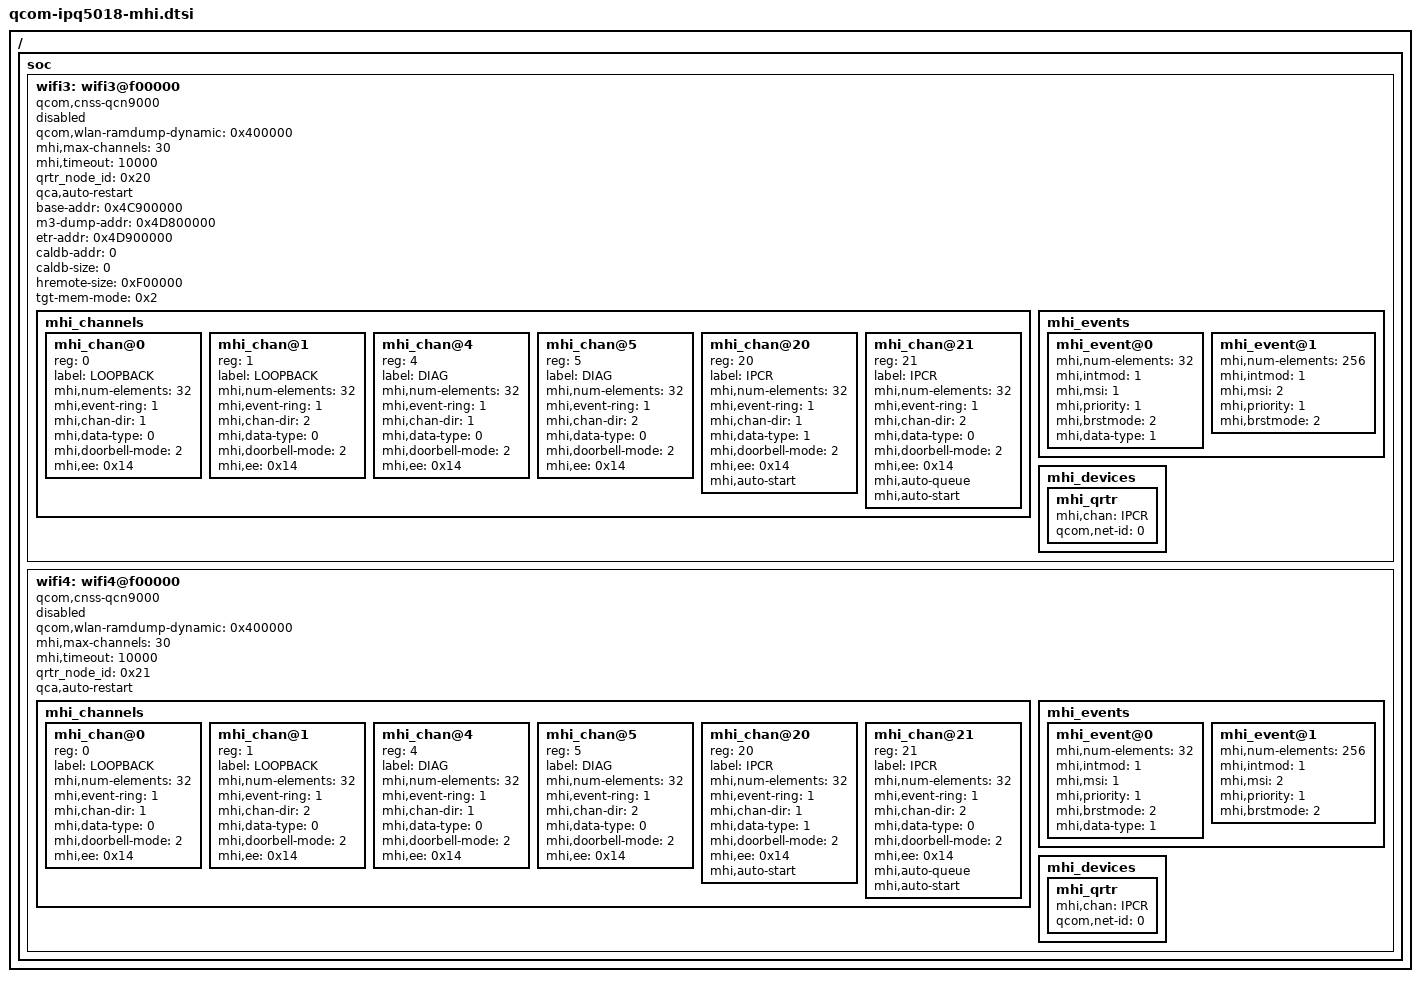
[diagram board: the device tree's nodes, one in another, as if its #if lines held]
/*
 * Copyright (c) 2017, 2020, The Linux Foundation. All rights reserved.
 *
 * Permission to use, copy, modify, and/or distribute this software for any
 * purpose with or without fee is hereby granted, provided that the above
 * copyright notice and this permission notice appear in all copies.
 *
 * THE SOFTWARE IS PROVIDED "AS IS" AND THE AUTHOR DISCLAIMS ALL WARRANTIES
 * WITH REGARD TO THIS SOFTWARE INCLUDING ALL IMPLIED WARRANTIES OF
 * MERCHANTABILITY AND FITNESS. IN NO EVENT SHALL THE AUTHOR BE LIABLE FOR
 * ANY SPECIAL, DIRECT, INDIRECT, OR CONSEQUENTIAL DAMAGES OR ANY DAMAGES
 * WHATSOEVER RESULTING FROM LOSS OF USE, DATA OR PROFITS, WHETHER IN AN
 * ACTION OF CONTRACT, NEGLIGENCE OR OTHER TORTIOUS ACTION, ARISING OUT OF
 * OR IN CONNECTION WITH THE USE OR PERFORMANCE OF THIS SOFTWARE.
 */


/ {

	soc {
		wifi3: wifi3@f00000 {
			compatible  = "qcom,cnss-qcn9000";
			qcom,wlan-ramdump-dynamic = <0x400000>;
			mhi,max-channels = <30>;
			mhi,timeout = <10000>;
			qrtr_node_id = <0x20>;
			qca,auto-restart;
#ifdef __IPQ_MEM_PROFILE_256_MB__
			/* QCN9000 tgt-mem-mode=2 layout - 17MB
			 * +=========+==============+=========+
			 * |  Region | Start Offset |   Size  |
			 * +---------+--------------+---------+
			 * | HREMOTE |  0x4C900000  |   15MB  |
			 * +---------+--------------+---------+
			 * | M3 Dump |  0x4D800000  |   1MB   |
			 * +---------+--------------+---------+
			 * |   ETR   |  0x4D900000  |   1MB   |
			 * +==================================+
			 */
			base-addr = <0x4C900000>;
			m3-dump-addr = <0x4D800000>;
			etr-addr = <0x4D900000>;
			caldb-addr = <0>;
			caldb-size = <0>;
			hremote-size = <0xF00000>;
			tgt-mem-mode = <0x2>;
#elif __IPQ_MEM_PROFILE_512_MB__
			/* QCN9000 tgt-mem-mode=1 layout - 30MB
			 * +=========+==============+=========+
			 * |  Region | Start Offset |   Size  |
			 * +---------+--------------+---------+
			 * | HREMOTE |  0x4CC00000  |   20MB  |
			 * +---------+--------------+---------+
			 * | M3 Dump |  0x4E000000  |   1MB   |
			 * +---------+--------------+---------+
			 * |   ETR   |  0x4E100000  |   1MB   |
			 * +---------+--------------+---------+
			 * |  Caldb  |  0x4E200000  |   8MB   |
			 * +==================================+
			 */
			base-addr = <0x4CC00000>;
			m3-dump-addr = <0x4E000000>;
			etr-addr = <0x4E100000>;
			caldb-addr = <0x4E200000>;
			caldb-size = <0x800000>;
			hremote-size = <0x1400000>;
			tgt-mem-mode = <0x1>;
#else
			/* QCN9000 tgt-mem-mode=0 layout - 45MB
		       * +=========+==============+=========+
		       * |  Region | Start Offset |   Size  |
		       * +---------+--------------+---------+
		       * | HREMOTE |  0x4CC00000  |   35MB  |
		       * +---------+--------------+---------+
		       * | M3 Dump |  0x4EF00000  |   1MB   |
		       * +---------+--------------+---------+
		       * |   ETR   |  0x4F000000  |   1MB   |
		       * +---------+--------------+---------+
		       * |  Caldb  |  0x4F100000  |   8MB   |
		       * +==================================+
		       */
			base-addr = <0x4CC00000>;
			m3-dump-addr = <0x4EF00000>;
			etr-addr = <0x4F000000>;
			caldb-addr = <0x4F100000>;
			hremote-size = <0x2300000>;
			caldb-size = <0x800000>;
			tgt-mem-mode = <0x0>;
#endif
			status = "disabled";

			#address-cells = <1>;
			#size-cells = <0>;

			mhi_channels {
				mhi_chan@0 {
					reg = <0>;
					label = "LOOPBACK";
					mhi,num-elements = <32>;
					mhi,event-ring = <1>;
					mhi,chan-dir = <1>;
					mhi,data-type = <0>;
					mhi,doorbell-mode = <2>;
					mhi,ee = <0x14>;
				};

				mhi_chan@1 {
					reg = <1>;
					label = "LOOPBACK";
					mhi,num-elements = <32>;
					mhi,event-ring = <1>;
					mhi,chan-dir = <2>;
					mhi,data-type = <0>;
					mhi,doorbell-mode = <2>;
					mhi,ee = <0x14>;
				};

				mhi_chan@4 {
					reg = <4>;
					label = "DIAG";
					mhi,num-elements = <32>;
					mhi,event-ring = <1>;
					mhi,chan-dir = <1>;
					mhi,data-type = <0>;
					mhi,doorbell-mode = <2>;
					mhi,ee = <0x14>;
				};

				mhi_chan@5 {
					reg = <5>;
					label = "DIAG";
					mhi,num-elements = <32>;
					mhi,event-ring = <1>;
					mhi,chan-dir = <2>;
					mhi,data-type = <0>;
					mhi,doorbell-mode = <2>;
					mhi,ee = <0x14>;
				};

				mhi_chan@20 {
					reg = <20>;
					label = "IPCR";
					mhi,num-elements = <32>;
					mhi,event-ring = <1>;
					mhi,chan-dir = <1>;
					mhi,data-type = <1>;
					mhi,doorbell-mode = <2>;
					mhi,ee = <0x14>;
					mhi,auto-start;
				};

				mhi_chan@21 {
					reg = <21>;
					label = "IPCR";
					mhi,num-elements = <32>;
					mhi,event-ring = <1>;
					mhi,chan-dir = <2>;
					mhi,data-type = <0>;
					mhi,doorbell-mode = <2>;
					mhi,ee = <0x14>;
					mhi,auto-queue;
					mhi,auto-start;
				};
			};

			mhi_events {
				mhi_event@0 {
					mhi,num-elements = <32>;
					mhi,intmod = <1>;
					mhi,msi = <1>;
					mhi,priority = <1>;
					mhi,brstmode = <2>;
					mhi,data-type = <1>;
				};

				mhi_event@1 {
					mhi,num-elements = <256>;
					mhi,intmod = <1>;
					mhi,msi = <2>;
					mhi,priority = <1>;
					mhi,brstmode = <2>;
				};
			};

			mhi_devices {
				mhi_qrtr {
					mhi,chan = "IPCR";
					qcom,net-id = <0>;
				};
			};
		};

		wifi4: wifi4@f00000 {
			compatible  = "qcom,cnss-qcn9000";
			qcom,wlan-ramdump-dynamic = <0x400000>;
			mhi,max-channels = <30>;
			mhi,timeout = <10000>;
			qrtr_node_id = <0x21>;
			qca,auto-restart;
			status = "disabled";

			#address-cells = <1>;
			#size-cells = <0>;

			mhi_channels {
				mhi_chan@0 {
					reg = <0>;
					label = "LOOPBACK";
					mhi,num-elements = <32>;
					mhi,event-ring = <1>;
					mhi,chan-dir = <1>;
					mhi,data-type = <0>;
					mhi,doorbell-mode = <2>;
					mhi,ee = <0x14>;
				};

				mhi_chan@1 {
					reg = <1>;
					label = "LOOPBACK";
					mhi,num-elements = <32>;
					mhi,event-ring = <1>;
					mhi,chan-dir = <2>;
					mhi,data-type = <0>;
					mhi,doorbell-mode = <2>;
					mhi,ee = <0x14>;
				};

				mhi_chan@4 {
					reg = <4>;
					label = "DIAG";
					mhi,num-elements = <32>;
					mhi,event-ring = <1>;
					mhi,chan-dir = <1>;
					mhi,data-type = <0>;
					mhi,doorbell-mode = <2>;
					mhi,ee = <0x14>;
				};

				mhi_chan@5 {
					reg = <5>;
					label = "DIAG";
					mhi,num-elements = <32>;
					mhi,event-ring = <1>;
					mhi,chan-dir = <2>;
					mhi,data-type = <0>;
					mhi,doorbell-mode = <2>;
					mhi,ee = <0x14>;
				};

				mhi_chan@20 {
					reg = <20>;
					label = "IPCR";
					mhi,num-elements = <32>;
					mhi,event-ring = <1>;
					mhi,chan-dir = <1>;
					mhi,data-type = <1>;
					mhi,doorbell-mode = <2>;
					mhi,ee = <0x14>;
					mhi,auto-start;
				};

				mhi_chan@21 {
					reg = <21>;
					label = "IPCR";
					mhi,num-elements = <32>;
					mhi,event-ring = <1>;
					mhi,chan-dir = <2>;
					mhi,data-type = <0>;
					mhi,doorbell-mode = <2>;
					mhi,ee = <0x14>;
					mhi,auto-queue;
					mhi,auto-start;
				};
			};

			mhi_events {
				mhi_event@0 {
					mhi,num-elements = <32>;
					mhi,intmod = <1>;
					mhi,msi = <1>;
					mhi,priority = <1>;
					mhi,brstmode = <2>;
					mhi,data-type = <1>;
				};

				mhi_event@1 {
					mhi,num-elements = <256>;
					mhi,intmod = <1>;
					mhi,msi = <2>;
					mhi,priority = <1>;
					mhi,brstmode = <2>;
				};
			};

			mhi_devices {
				mhi_qrtr {
					mhi,chan = "IPCR";
					qcom,net-id = <0>;
				};
			};
		};
	};
};
